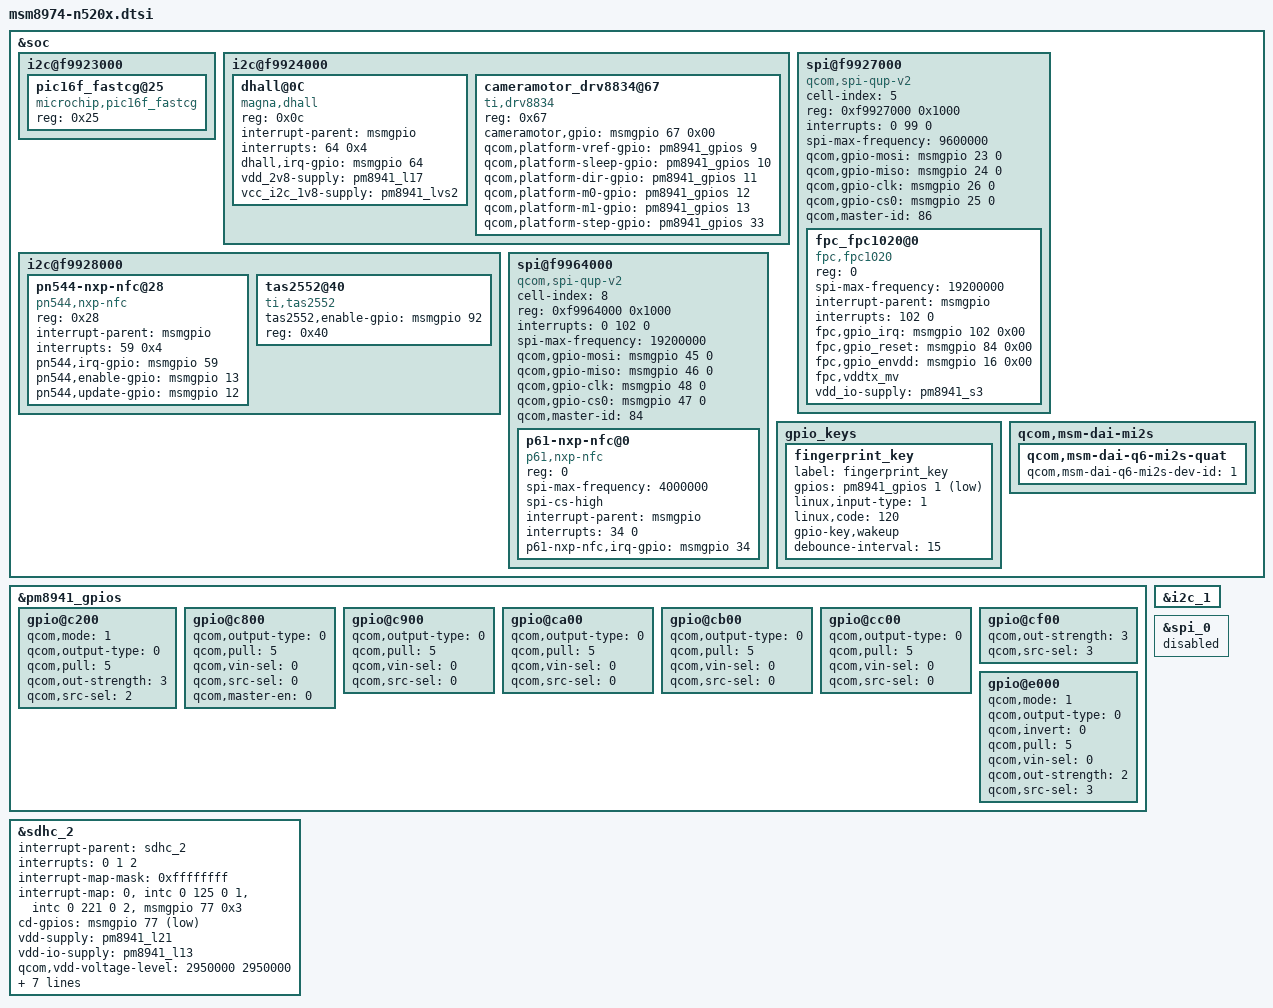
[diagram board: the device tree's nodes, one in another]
/* Copyright (c) 2012-2013, The Linux Foundation. All rights reserved.
 *
 * This program is free software; you can redistribute it and/or modify
 * it under the terms of the GNU General Public License version 2 and
 * only version 2 as published by the Free Software Foundation.
 *
 * This program is distributed in the hope that it will be useful,
 * but WITHOUT ANY WARRANTY; without even the implied warranty of
 * MERCHANTABILITY or FITNESS FOR A PARTICULAR PURPOSE.  See the
 * GNU General Public License for more details.
 */

/include/ "msm8974-oppo-common.dtsi"
/include/ "msm8974-oppo-camera.dtsi"
/include/ "msm8974-n520x-camera-sensor.dtsi"
/include/ "msm8974-oppo-input.dtsi"
/include/ "msm8974-oppo-usb.dtsi"
/include/ "msm8974-oppo-misc.dtsi"
/include/ "msm8974-oppo-pm.dtsi"
/include/ "msm8974-oppo-nfc.dtsi"
/include/ "msm8974-oppo-regulator.dtsi"
/include/ "msm8974-n520x-sound.dtsi"
/include/ "msm8974-oppo-leds.dtsi"
/include/ "msm8974-n520x-leds.dtsi"
/include/ "msm8974-n520x-mdss.dtsi"

&soc {
	i2c@f9923000 {
		pic16f_fastcg@25 {
			status = "okay";
			compatible = "microchip,pic16f_fastcg";
			reg = <0x25>;
		};
	};

	i2c@f9924000 {
		dhall@0C {
			compatible = "magna,dhall";
			reg = <0x0c>;
			interrupt-parent = <&msmgpio>;
			interrupts = <64 0x4>;
			dhall,irq-gpio = <&msmgpio 64 0x2008>;
			vdd_2v8-supply = <&pm8941_l17>;
			vcc_i2c_1v8-supply = <&pm8941_lvs2>;
		};

		cameramotor_drv8834@67 {
			compatible = "ti,drv8834";
			reg = <0x67>;
			cameramotor,gpio = <&msmgpio 67 0x00>;
			qcom,platform-vref-gpio = <&pm8941_gpios 9 0>;
			qcom,platform-sleep-gpio = <&pm8941_gpios 10 0>;
			qcom,platform-dir-gpio = <&pm8941_gpios 11 0>;
			qcom,platform-m0-gpio = <&pm8941_gpios 12 0>;
			qcom,platform-m1-gpio = <&pm8941_gpios 13 0>;
			qcom,platform-step-gpio = <&pm8941_gpios 33 0>;
		};
	};

	spi@f9927000 {
		compatible = "qcom,spi-qup-v2";

		cell-index = <5>;
		reg-names = "spi_physical";
		reg = <0xf9927000 0x1000>;
		interrupt-names = "spi5_irq";
		interrupts = <0 99 0>;

		spi-max-frequency = <9600000>;
		#address-cells = <1>;
		#size-cells = <0>;

		qcom,gpio-mosi = <&msmgpio 23 0>;
		qcom,gpio-miso = <&msmgpio 24 0>;
		qcom,gpio-clk  = <&msmgpio 26 0>;
		qcom,gpio-cs0  = <&msmgpio 25 0>;

		qcom,master-id = <86>;

		fpc_fpc1020@0 {
			compatible = "fpc,fpc1020";
			reg = <0>;
			spi-max-frequency = <19200000>;
			interrupt-parent = <&msmgpio>;
			interrupts = <102 0>;
			fpc,gpio_irq = <&msmgpio 102 0x00>;
			fpc,gpio_reset = <&msmgpio 84 0x00>;
			fpc,gpio_envdd = <&msmgpio 16 0x00>;
			fpc,vddtx_mv;
			vdd_io-supply = <&pm8941_s3>;
		};
	};

	i2c@f9928000 {
		pn544-nxp-nfc@28 {
			compatible = "pn544,nxp-nfc";
			reg = <0x28>;
			interrupt-parent = <&msmgpio>;
			interrupts = <59 0x4>;
			pn544,irq-gpio = <&msmgpio 59 0x00>;
			pn544,enable-gpio = <&msmgpio 13 0x00>;
			pn544,update-gpio = <&msmgpio 12 0x00>;
		};

		tas2552@40 {
			status = "okay";
			compatible = "ti,tas2552";
			tas2552,enable-gpio = <&msmgpio 92 0x00>;
			reg = <0x40>;
		};
	};

	spi@f9964000 {
		compatible = "qcom,spi-qup-v2";

		cell-index = <8>;
		reg-names = "spi_physical";
		reg = <0xf9964000 0x1000>;
		interrupt-names = "spi8_irq";
		interrupts = <0 102 0>;

		spi-max-frequency = <19200000>;
		#address-cells = <1>;
		#size-cells = <0>;

		qcom,gpio-mosi = <&msmgpio 45 0>;
		qcom,gpio-miso = <&msmgpio 46 0>;
		qcom,gpio-clk  = <&msmgpio 48 0>;
		qcom,gpio-cs0  = <&msmgpio 47 0>;

		qcom,master-id = <84>;

		p61-nxp-nfc@0 {
			compatible = "p61,nxp-nfc";
			reg = <0>;
			spi-max-frequency = <4000000>;
			spi-cs-high;
			interrupt-parent = <&msmgpio>;
			interrupts = <34 0>;
			p61-nxp-nfc,irq-gpio = <&msmgpio 34 0x00>;
		};
	};

	gpio_keys {
		fingerprint_key {
			label = "fingerprint_key";
			gpios = <&pm8941_gpios 1 0x1>;
			linux,input-type = <1>;
			linux,code = <120>;
			gpio-key,wakeup;
			debounce-interval = <15>;
		};
	};

	qcom,msm-dai-mi2s {
		qcom,msm-dai-q6-mi2s-quat {
			qcom,msm-dai-q6-mi2s-dev-id = <1>;
		};
	};
};

&pm8941_gpios {
	gpio@c200 { /* GPIO 3 */
		qcom,mode = <1>;		/* QPNP_PIN_MODE_DIG_OUT */
		qcom,output-type = <0>;		/* QPNP_PIN_OUT_BUF_CMOS */
		qcom,pull = <5>;		/* QPNP_PIN_PULL_NO */
		qcom,out-strength = <3>;
		qcom,src-sel = <2>;
	};

	gpio@c800 { /* GPIO 9 */
		qcom,output-type = <0>;		/* QPNP_PIN_OUT_BUF_CMOS */
		qcom,pull = <5>;		/* QPNP_PIN_PULL_NO */
		qcom,vin-sel = <0>;		/* QPNP_PIN_VIN2 VPH_PWR */
		qcom,src-sel = <0>;		/* QPNP_PIN_SEL_FUNC_CONSTANT */
		qcom,master-en = <0>;
	};

	gpio@c900 { /* GPIO 10 */
		qcom,output-type = <0>;		/* QPNP_PIN_OUT_BUF_CMOS */
		qcom,pull = <5>;		/* QPNP_PIN_PULL_NO */
		qcom,vin-sel = <0>;		/* QPNP_PIN_VIN2 */
		qcom,src-sel = <0>;		/* QPNP_PIN_SEL_FUNC_CONSTANT */
	};

	gpio@ca00 { /* GPIO 11 */
		qcom,output-type = <0>;		/* QPNP_PIN_OUT_BUF_CMOS */
		qcom,pull = <5>;		/* QPNP_PIN_PULL_NO */
		qcom,vin-sel = <0>;		/* QPNP_PIN_VIN2 */
		qcom,src-sel = <0>;		/* QPNP_PIN_SEL_FUNC_CONSTANT */
	};

	gpio@cb00 { /* GPIO 12 */
		qcom,output-type = <0>;		/* QPNP_PIN_OUT_BUF_CMOS */
		qcom,pull = <5>;		/* QPNP_PIN_PULL_NO */
		qcom,vin-sel = <0>;		/* QPNP_PIN_VIN2 */
		qcom,src-sel = <0>;		/* QPNP_PIN_SEL_FUNC_CONSTANT */
	};

	gpio@cc00 { /* GPIO 13 */
		qcom,output-type = <0>;		/* QPNP_PIN_OUT_BUF_CMOS */
		qcom,pull = <5>;		/* QPNP_PIN_PULL_NO */
		qcom,vin-sel = <0>;		/* QPNP_PIN_VIN2 */
		qcom,src-sel = <0>;		/* QPNP_PIN_SEL_FUNC_CONSTANT */
	};

	gpio@cf00 { /* GPIO 16 */
		qcom,out-strength = <3>;
		qcom,src-sel = <3>;		/* QPNP_PIN_SEL_FUNC_2  */
	};

	gpio@e000 { /* GPIO 33 */
		qcom,mode = <1>;		/* QPNP_PIN_MODE_DIG_OUT */
		qcom,output-type = <0>;		/* QPNP_PIN_OUT_BUF_CMOS */
		qcom,invert = <0>;		/* QPNP_PIN_INVERT_DISABLE */
		qcom,pull = <5>;		/* QPNP_PIN_PULL_NO */
		qcom,vin-sel = <0>;		/* QPNP_PIN_VIN2, VREG_S3A */
		qcom,out-strength = <2>;	/* QPNP_PIN_OUT_STRENGTH_MED */
		qcom,src-sel = <3>;		/* QPNP_PIN_SEL_FUNC_2 */
	};
};

&i2c_1 {
	status = "ok";
};

&spi_0 {
	status = "disabled";
};

&sdhc_2 {
	#address-cells = <0>;
	interrupt-parent = <&sdhc_2>;
	interrupts = <0 1 2>;
	#interrupt-cells = <1>;
	interrupt-map-mask = <0xffffffff>;
	interrupt-map = <0 &intc 0 125 0
			1 &intc 0 221 0
			2 &msmgpio 77 0x3>;
	interrupt-names = "hc_irq", "pwr_irq", "status_irq";
	cd-gpios = <&msmgpio 77 0x1>;

	vdd-supply = <&pm8941_l21>;
	vdd-io-supply = <&pm8941_l13>;

	qcom,vdd-voltage-level = <2950000 2950000>;
	qcom,vdd-current-level = <9000 800000>;

	qcom,vdd-io-voltage-level = <1800000 2950000>;
	qcom,vdd-io-current-level = <6 22000>;

	qcom,pad-pull-on = <0x0 0x3 0x3>; /* no-pull, pull-up, pull-up */
	qcom,pad-pull-off = <0x0 0x3 0x3>; /* no-pull, pull-up, pull-up */
	qcom,pad-drv-on = <0x7 0x4 0x4>; /* 16mA, 10mA, 10mA */
	qcom,pad-drv-off = <0x0 0x0 0x0>; /* 2mA, 2mA, 2mA */
	status = "ok";
};
